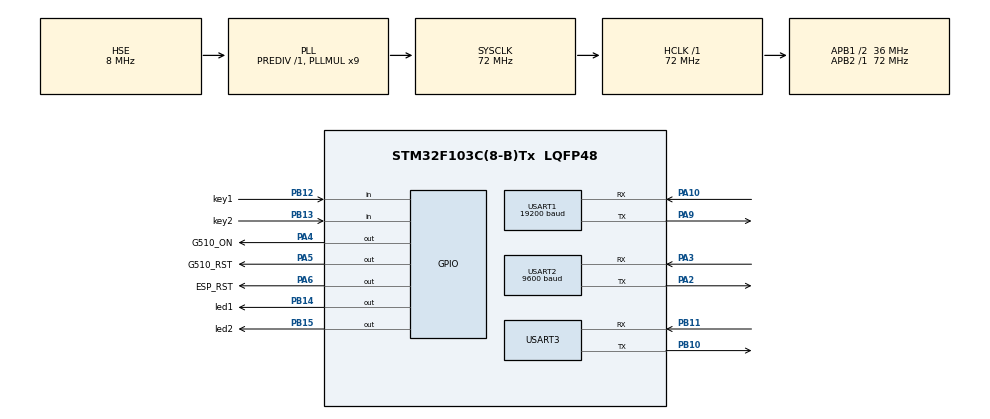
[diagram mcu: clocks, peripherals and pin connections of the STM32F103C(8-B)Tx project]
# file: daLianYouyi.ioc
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Mcu.Family=STM32F1
Mcu.Name=STM32F103C(8-B)Tx
Mcu.Package=LQFP48
NVIC.PriorityGroup=NVIC_PRIORITYGROUP_4
NVIC.TIM2_IRQn=true\:1\:0\:true\:true\:true\:1\:true
NVIC.USART1_IRQn=true\:0\:0\:false\:false\:true\:true
NVIC.USART2_IRQn=true\:0\:0\:false\:true\:true\:2\:true
PA10.Mode=Asynchronous
PA10.Signal=USART1_RX
PA13.Mode=Serial_Wire
PA13.Signal=SYS_JTMS-SWDIO
PA14.Mode=Serial_Wire
PA14.Signal=SYS_JTCK-SWCLK
PA2.Mode=Asynchronous
PA2.Signal=USART2_TX
PA3.Mode=Asynchronous
PA3.Signal=USART2_RX
PA4.GPIO_Label=G510_ON
PA4.Signal=GPIO_Output
PA5.GPIO_Label=G510_RST
PA5.PinState=GPIO_PIN_SET
PA5.Signal=GPIO_Output
PA6.GPIO_Label=ESP_RST
PA6.PinState=GPIO_PIN_SET
PA6.Signal=GPIO_Output
PA9.Mode=Asynchronous
PA9.Signal=USART1_TX
PB10.Mode=Asynchronous
PB10.Signal=USART3_TX
PB11.Mode=Asynchronous
PB11.Signal=USART3_RX
PB12.GPIO_Label=key1
PB12.GPIO_PuPd=GPIO_PULLUP
PB12.Signal=GPIO_Input
PB13.GPIO_Label=key2
PB13.GPIO_PuPd=GPIO_PULLUP
PB13.Signal=GPIO_Input
PB14.GPIO_Label=led1
PB14.Signal=GPIO_Output
PB15.GPIO_Label=led2
PB15.Signal=GPIO_Output
PD0-OSC_IN.Mode=HSE-External-Oscillator
PD0-OSC_IN.Signal=RCC_OSC_IN
PD1-OSC_OUT.Mode=HSE-External-Oscillator
PD1-OSC_OUT.Signal=RCC_OSC_OUT
ProjectManager.HeapSize=0x800
ProjectManager.StackSize=0x2000
ProjectManager.TargetToolchain=Other Toolchains (GPDSC)
RCC.AHBFreq_Value=72000000
RCC.APB1CLKDivider=RCC_HCLK_DIV2
RCC.APB1Freq_Value=36000000
RCC.APB1TimFreq_Value=72000000
RCC.APB2Freq_Value=72000000
RCC.APB2TimFreq_Value=72000000
RCC.HCLKFreq_Value=72000000
RCC.PLLMUL=RCC_PLL_MUL9
RCC.PLLSourceVirtual=RCC_PLLSOURCE_HSE
RCC.SYSCLKFreq_VALUE=72000000
RCC.SYSCLKSource=RCC_SYSCLKSOURCE_PLLCLK
RCC.USBFreq_Value=72000000
TIM2.Period=10-1
TIM2.Prescaler=7200-1
USART1.BaudRate=19200
USART1.VirtualMode=VM_ASYNC
USART2.BaudRate=9600
USART2.VirtualMode=VM_ASYNC
USART3.VirtualMode=VM_ASYNC
VP_TIM2_VS_ClockSourceINT.Mode=Internal
board=GizCBT6

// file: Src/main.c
/* USER CODE BEGIN Header */
/**
  ******************************************************************************
  * @file           : main.c
  * @brief          : Main program body
  ******************************************************************************
  ** This notice applies to any and all portions of this file
  * that are not between comment pairs USER CODE BEGIN and
  * USER CODE END. Other portions of this file, whether
  * inserted by the user or by software development tools
  * are owned by their respective copyright owners.
  *
  * COPYRIGHT(c) 2019 STMicroelectronics
  *
  * Redistribution and use in source and binary forms, with or without modification,
  * are permitted provided that the following conditions are met:
  *   1. Redistributions of source code must retain the above copyright notice,
  *      this list of conditions and the following disclaimer.
  *   2. Redistributions in binary form must reproduce the above copyright notice,
  *      this list of conditions and the following disclaimer in the documentation
  *      and/or other materials provided with the distribution.
  *   3. Neither the name of STMicroelectronics nor the names of its contributors
  *      may be used to endorse or promote products derived from this software
  *      without specific prior written permission.
  *
  * THIS SOFTWARE IS PROVIDED BY THE COPYRIGHT HOLDERS AND CONTRIBUTORS "AS IS"
  * AND ANY EXPRESS OR IMPLIED WARRANTIES, INCLUDING, BUT NOT LIMITED TO, THE
  * IMPLIED WARRANTIES OF MERCHANTABILITY AND FITNESS FOR A PARTICULAR PURPOSE ARE
  * DISCLAIMED. IN NO EVENT SHALL THE COPYRIGHT HOLDER OR CONTRIBUTORS BE LIABLE
  * FOR ANY DIRECT, INDIRECT, INCIDENTAL, SPECIAL, EXEMPLARY, OR CONSEQUENTIAL
  * DAMAGES (INCLUDING, BUT NOT LIMITED TO, PROCUREMENT OF SUBSTITUTE GOODS OR
  * SERVICES; LOSS OF USE, DATA, OR PROFITS; OR BUSINESS INTERRUPTION) HOWEVER
  * CAUSED AND ON ANY THEORY OF LIABILITY, WHETHER IN CONTRACT, STRICT LIABILITY,
  * OR TORT (INCLUDING NEGLIGENCE OR OTHERWISE) ARISING IN ANY WAY OUT OF THE USE
  * OF THIS SOFTWARE, EVEN IF ADVISED OF THE POSSIBILITY OF SUCH DAMAGE.
  *
  ******************************************************************************
  */
/* USER CODE END Header */

#include "main.h"
#include "tim.h"
#include "usart.h"
#include "gpio.h"

/* USER CODE BEGIN Includes */

#include "gizwits_product.h"
#include "common.h"
#include "modbusToPC.h"

/* USER CODE END Includes */

void SystemClock_Config(void);
static void MX_NVIC_Init(void);

int main(void)
{

  /* MCU Configuration--------------------------------------------------------*/

  /* Reset of all peripherals, Initializes the Flash interface and the Systick. */
  HAL_Init();

  /* Configure the system clock */
  SystemClock_Config();

  /* Initialize all configured peripherals */
  MX_GPIO_Init();
  MX_TIM2_Init();
  MX_USART1_UART_Init();
  MX_USART2_UART_Init();
  MX_USART3_UART_Init();

  /* Initialize interrupts */
  MX_NVIC_Init();
  /* USER CODE BEGIN 2 */

  timerInit();
  uartInit();
  userInit();
  gizwitsInit();
  GIZWITS_LOG("MCU Init Success \n");

  /* USER CODE END 2 */

  /* Infinite loop */
  while (1)
  {

    /* USER CODE BEGIN 3 */

	  modbusPull();
	  modbusReceive();
	  userHandle();
	  gizwitsHandle((dataPoint_t *)&currentDataPoint);

  }
  /* USER CODE END 3 */
}

void SystemClock_Config(void)
{
  RCC_OscInitTypeDef RCC_OscInitStruct = {0};
  RCC_ClkInitTypeDef RCC_ClkInitStruct = {0};

  /**Initializes the CPU, AHB and APB busses clocks
  */
  RCC_OscInitStruct.OscillatorType = RCC_OSCILLATORTYPE_HSE;
  RCC_OscInitStruct.HSEState = RCC_HSE_ON;
  RCC_OscInitStruct.HSEPredivValue = RCC_HSE_PREDIV_DIV1;
  RCC_OscInitStruct.HSIState = RCC_HSI_ON;
  RCC_OscInitStruct.PLL.PLLState = RCC_PLL_ON;
  RCC_OscInitStruct.PLL.PLLSource = RCC_PLLSOURCE_HSE;
  RCC_OscInitStruct.PLL.PLLMUL = RCC_PLL_MUL9;
  if (HAL_RCC_OscConfig(&RCC_OscInitStruct) != HAL_OK)
  {
    Error_Handler();
  }
  /**Initializes the CPU, AHB and APB busses clocks
  */
  RCC_ClkInitStruct.ClockType = RCC_CLOCKTYPE_HCLK|RCC_CLOCKTYPE_SYSCLK
                              |RCC_CLOCKTYPE_PCLK1|RCC_CLOCKTYPE_PCLK2;
  RCC_ClkInitStruct.SYSCLKSource = RCC_SYSCLKSOURCE_PLLCLK;
  RCC_ClkInitStruct.AHBCLKDivider = RCC_SYSCLK_DIV1;
  RCC_ClkInitStruct.APB1CLKDivider = RCC_HCLK_DIV2;
  RCC_ClkInitStruct.APB2CLKDivider = RCC_HCLK_DIV1;

  if (HAL_RCC_ClockConfig(&RCC_ClkInitStruct, FLASH_LATENCY_2) != HAL_OK)
  {
    Error_Handler();
  }
}

/**
  * @brief NVIC Configuration.
  * @retval None
  */
static void MX_NVIC_Init(void)
{
  /* TIM2_IRQn interrupt configuration */
  HAL_NVIC_SetPriority(TIM2_IRQn, 1, 0);
  HAL_NVIC_EnableIRQ(TIM2_IRQn);
  /* USART2_IRQn interrupt configuration */
  HAL_NVIC_SetPriority(USART2_IRQn, 0, 0);
  HAL_NVIC_EnableIRQ(USART2_IRQn);
}

void Error_Handler(void)
{
}

/************************ (C) COPYRIGHT STMicroelectronics *****END OF FILE****/
